# ATmega1609 register map
Vendor: Atmel; File version: 1.0
CPU: other r0p0, little endian, no MPU, no FPU, 4 interrupt priority bits
Registers are 8-bit, read-write, reset 0x0 unless marked. A register's access mark holds for its fields unless they carry their own. Offsets are from the block's base; lines under a group give offsets from that group; [hi:lo] are bit positions; {n}, {i} and the like mark numbered series; 'fields as' and 'values as' point back to an identical list; <NAME> marks a mode.

## Memory map
0x00800000 VPORTA size 0x4 — Virtual Ports
0x00800004 VPORTB size 0x4 — Virtual Ports
0x00800008 VPORTC size 0x4 — Virtual Ports
0x0080000C VPORTD size 0x4 — Virtual Ports
0x00800010 VPORTE size 0x4 — Virtual Ports
0x00800014 VPORTF size 0x4 — Virtual Ports
0x0080001C GPIO size 0x4 — General Purpose IO
0x00800034 CPU blocks up to offset 0xB
0x00800040 RSTCTRL size 0x2 — Reset controller
0x00800050 SLPCTRL size 0x1 — Sleep Controller
0x00800060 CLKCTRL blocks up to offset 0x1D — Clock controller
0x00800080 BOD blocks up to offset 0xC — Bod interface
0x008000A0 VREF size 0x2 — Voltage reference
0x00800100 WDT size 0x2 — Watch-Dog Timer
0x00800110 CPUINT size 0x4 — Interrupt Controller
0x00800120 CRCSCAN size 0x3
0x00800140 RTC blocks up to offset 0x16 — Real-Time Counter
0x00800180 EVSYS blocks up to offset 0x38 — Event System
0x008001C0 CCL blocks up to offset 0x18 — Configurable Custom Logic
0x00800400 PORTA blocks up to offset 0x18 — I/O Ports
0x00800420 PORTB blocks up to offset 0x18 — I/O Ports
0x00800440 PORTC blocks up to offset 0x18 — I/O Ports
0x00800460 PORTD blocks up to offset 0x18 — I/O Ports
0x00800480 PORTE blocks up to offset 0x18 — I/O Ports
0x008004A0 PORTF blocks up to offset 0x18 — I/O Ports
0x008005E0 PORTMUX size 0x6 — Port Multiplexer
0x00800600 ADC0 blocks up to offset 0x17 — Analog to Digital Converter
0x00800680 AC0 blocks up to offset 0x8 — Analog Comparator
0x00800800 USART0 size 0xF — Universal Synchronous and Asynchronous Receiver and Transmitter
0x00800820 USART1 size 0xF — Universal Synchronous and Asynchronous Receiver and Transmitter
0x00800840 USART2 size 0xF — Universal Synchronous and Asynchronous Receiver and Transmitter
0x00800860 USART3 size 0xF — Universal Synchronous and Asynchronous Receiver and Transmitter
0x008008A0 TWI0 size 0xF — Two-Wire Interface
0x008008C0 SPI0 size 0x5 — Serial Peripheral Interface
0x00800A00 TCA0 blocks up to offset 0x3E — 16-bit Timer/Counter Type A
0x00800A80 TCB0 blocks up to offset 0xE — 16-bit Timer Type B
0x00800A90 TCB1 blocks up to offset 0xE — 16-bit Timer Type B
0x00800AA0 TCB2 blocks up to offset 0xE — 16-bit Timer Type B
0x00800AB0 TCB3 blocks up to offset 0xE — 16-bit Timer Type B
0x00800F01 SYSCFG blocks up to offset 0x19 — System Configuration Registers
0x00801000 NVMCTRL blocks up to offset 0xA — Non-volatile Memory Controller
0x00801100 SIGROW blocks up to offset 0x30 — Signature row
0x00801280 FUSE blocks up to offset 0x9 — Fuses
0x0080128A LOCKBIT size 0x1
0x00801300 USERROW size 0x40

## Interrupts
1 CRCSCAN_NMI (CPU)
2 BOD_VLM (CPU)
3 RTC_CNT (CPU)
4 RTC_PIT (CPU)
5 CCL_CCL (CPU)
6 PORTA_PORT (CPU)
7 TCA0_LUNF_OVF (CPU)
8 TCA0_HUNF (CPU)
9 TCA0_CMP0_LCMP0 (CPU)
10 TCA0_CMP1_LCMP1 (CPU)
11 TCA0_CMP2_LCMP2 (CPU)
12 TCB0_INT (CPU)
13 TCB1_INT (CPU)
14 TWI0_TWIS (CPU)
15 TWI0_TWIM (CPU)
16 SPI0_INT (CPU)
17 USART0_RXC (CPU)
18 USART0_DRE (CPU)
19 USART0_TXC (CPU)
20 PORTD_PORT (CPU)
21 AC0_AC (CPU)
22 ADC0_RESRDY (CPU)
23 ADC0_WCOMP (CPU)
24 PORTC_PORT (CPU)
25 TCB2_INT (CPU)
26 USART1_RXC (CPU)
27 USART1_DRE (CPU)
28 USART1_TXC (CPU)
29 PORTF_PORT (CPU)
30 NVMCTRL_EE (CPU)
31 USART2_RXC (CPU)
32 USART2_DRE (CPU)
33 USART2_TXC (CPU)
34 PORTB_PORT (CPU)
35 PORTE_PORT (CPU)
36 TCB3_INT (CPU)
37 USART3_RXC (CPU)
38 USART3_DRE (CPU)
39 USART3_TXC (CPU)

## AC0 — Analog Comparator
Base 0x00800680
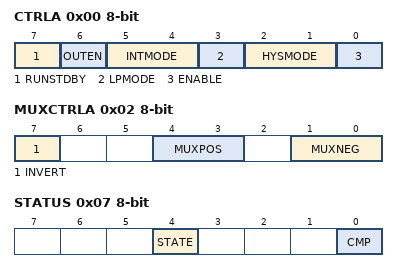
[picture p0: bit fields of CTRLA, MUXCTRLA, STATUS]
0x00 CTRLA — Control A
  [7] RUNSTDBY — Run in Standby Mode
  [6] OUTEN — Output Buffer Enable
  [5:4] INTMODE — Interrupt Mode
    0=BOTHEDGE (Any Edge); 2=NEGEDGE (Negative Edge); 3=POSEDGE (Positive Edge)
  [3] LPMODE — Low Power Mode
    0=DIS (Low power mode disabled); 1=EN (Low power mode enabled)
  [2:1] HYSMODE — Hysteresis Mode
    0=OFF (No hysteresis); 1=10mV hysteresis; 2=25mV hysteresis; 3=50mV hysteresis
  [0] ENABLE
0x02 MUXCTRLA — Mux Control A
  [7] INVERT — Invert AC Output
  [4:3] MUXPOS — Positive Input MUX Selection
    {v}=PIN{v} (Positive Pin {v}) (v=0..3)
  [1:0] MUXNEG — Negative Input MUX Selection
    0=PIN0 (Negative Pin 0); 1=PIN1 (Negative Pin 1); 2=PIN2 (Negative Pin 2); 3=DACREF (DAC Voltage Reference)
0x04 DACREF — Referance scale control
  [7:0] DATA — DAC voltage reference
0x06 INTCTRL — Interrupt Control
  [0] CMP — Analog Comparator 0 Interrupt Enable
0x07 STATUS
  [4] STATE ro — Analog Comparator State
  [0] CMP — Analog Comparator Interrupt Flag
